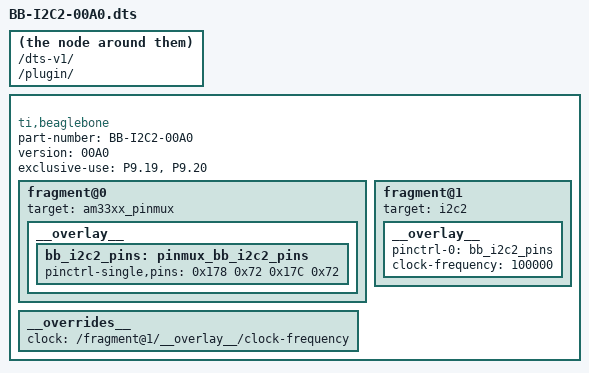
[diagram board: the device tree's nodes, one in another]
// SPDX-License-Identifier: GPL-2.0-only
/dts-v1/;
/plugin/;

{
    compatible = "ti,beaglebone", "ti,beaglebone-black";
    part-number = "BB-I2C2-00A0";
    version = "00A0";

    exclusive-use = "P9.19", "P9.20";

    fragment@0 {
        target = <&am33xx_pinmux>;
        __overlay__ {
            bb_i2c2_pins: pinmux_bb_i2c2_pins {
                pinctrl-single,pins = <
                    0x178 0x72  /* P9_20.i2c2_sda, mode 2, pull-up */
                    0x17C 0x72  /* P9_19.i2c2_scl, mode 2, pull-up */
                >;
            };
        };
    };

    fragment@1 {
        target = <&i2c2>;
        __overlay__ {
            status = "okay";
            pinctrl-names = "default";
            pinctrl-0 = <&bb_i2c2_pins>;
            clock-frequency = <100000>;  /* standard 100 kHz; change to 400000 if desired */
        };
    };

    __overrides__ {
        clock = /fragment@1/__overlay__/clock-frequency;
    };
};
